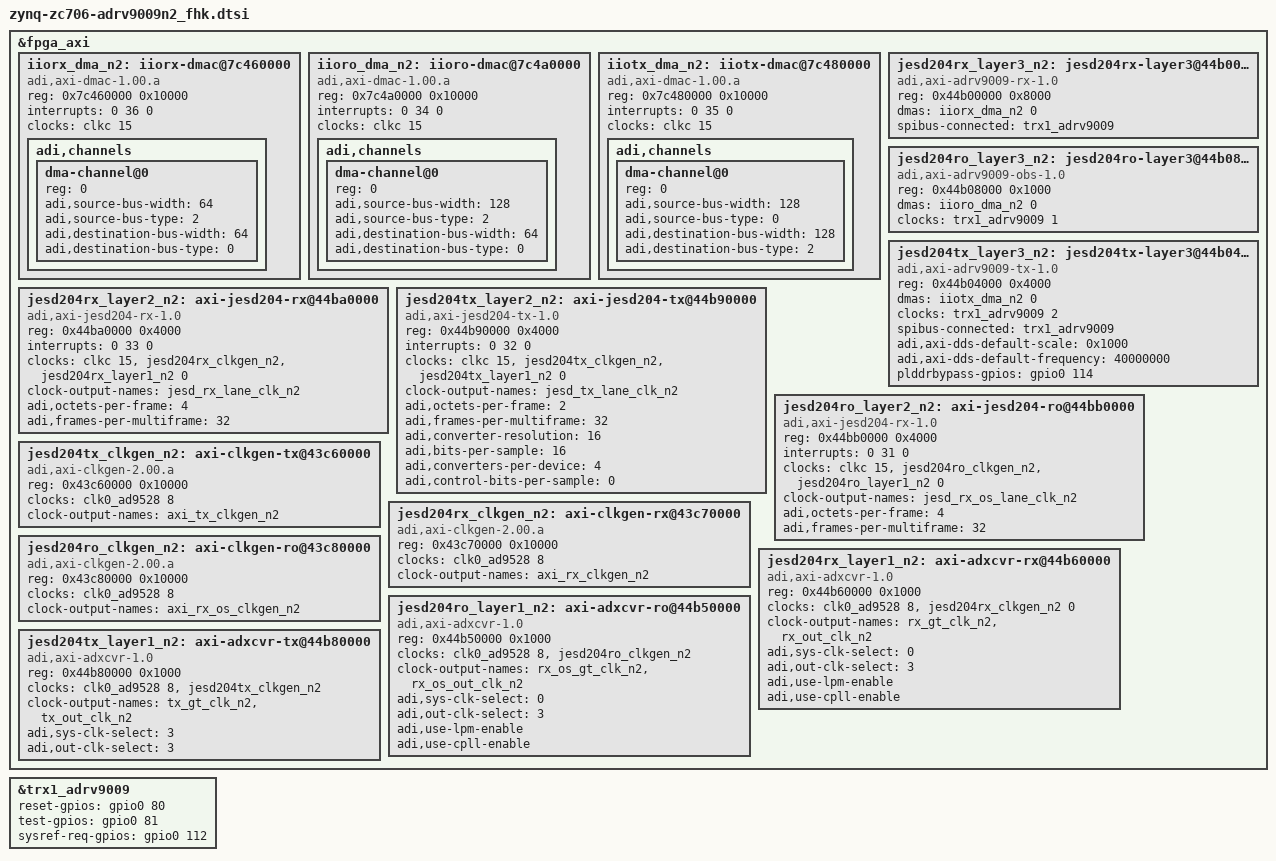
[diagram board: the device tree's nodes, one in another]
/* 
Author	: Jacky.Wang <kenwj@sina.com>
NOTICE	:
   clocks : means "clocks_input" actually
   clock-names : the name is "aligned" with the corresponding driver
interrupts of zynq7k:
  PL to PS Interrupts:
    IRQF2P[ 7: 0] input, SPI: Numbers [68:61].
    IRQF2P[15: 8] input, SPI: Numbers [91:84].
    IRQF2P[19:16] input, PPI: nFIQ, nIRQ (both CPUs).
  PS to PL Interrupts:
    IRQP2F[27: 0] Output, I/O peripherals received and forwarded to the interrupt controller.

History	:
  base: branch "adrv9009_zc706", "arch\arm\boot\dts\zynq-zc706-adv7511-adrv9009.dts"
  change: clock-tree/interrupts per FHK-RFB (1*AD9528+2*AD9009)
  reference: https://ez.analog.com/wide-band-rf-transceivers/
    design-support-adrv9008-1-adrv9008-2-adrv9009/f/discussions/
    100583/adrv9009-custom-profile/300558
  change: Xilinx DPD integration, FHK DMA datapath verification
*/
&fpga_axi {
	/* 0 (AXI_DMAC_TYPE_AXI_MM): Memory mapped AXI interface
	   1 (AXI_DMAC_TYPE_AXI_STREAM): Streaming AXI interface
	   2 (AXI_DMAC_TYPE_AXI_FIFO): FIFO interface */
	iiorx_dma_n2: iiorx-dmac@7c460000 {
		compatible = "adi,axi-dmac-1.00.a";
		reg = <0x7c460000 0x10000>;
		#dma-cells = <1>;
		interrupts = <0 36 0>; // UG858, Table 7-4: IRQF2P[7] -> IRQ[68-32]
		clocks = <&clkc 15>; // 15/fclk0=100MHz <- 17/fclk2=250MHz
		//clocks = <&clkc 15>, <&clkc 17>, <&misc_clk_0>;
		//clock-names = "s_axi_aclk", "m_dest_axi_aclk", "fifo_wr_clk";

		adi,channels {
			#size-cells = <0>;
			#address-cells = <1>;

			dma-channel@0 {
				reg = <0>;
				adi,source-bus-width = <64>;
				adi,source-bus-type = <2>;
				adi,destination-bus-width = <64>;
				adi,destination-bus-type = <0>;
			};
		};
	};

	iioro_dma_n2: iioro-dmac@7c4a0000  {
		compatible = "adi,axi-dmac-1.00.a";
		reg = <0x7c4a0000  0x10000>;
		#dma-cells = <1>;
		interrupts = <0 34 0>; // UG858, Table 7-4: IRQF2P[5] -> IRQ[66-32]
		clocks = <&clkc 15>; // 15/fclk0=100MHz <- 17/fclk2=250MHz
		//clocks = <&clkc 15>, <&clkc 17>, <&misc_clk_0>;
		//clock-names = "s_axi_aclk", "m_dest_axi_aclk", "fifo_wr_clk";

		adi,channels {
			#size-cells = <0>;
			#address-cells = <1>;

			dma-channel@0 {
				reg = <0>;
				adi,source-bus-width = <128>;// TODO: master for 122profile: 128
				adi,source-bus-type = <2>;
				adi,destination-bus-width = <64>;
				adi,destination-bus-type = <0>;
			};
		};
	};

	iiotx_dma_n2: iiotx-dmac@7c480000 {
		compatible = "adi,axi-dmac-1.00.a";
		reg = <0x7c480000 0x10000>;
		#dma-cells = <1>;
		interrupts = <0 35 0>; // UG858, Table 7-4: IRQF2P[6] -> IRQ[67-32]
		clocks = <&clkc 15>; // 15/fclk0=100MHz <- 17/fclk2=250MHz
		//clocks = <&clkc 15>, <&clkc 17>, <&clkc 17>;
		//clock-names = "s_axi_aclk", "m_src_axi_aclk", "m_axis_aclk";

		adi,channels {
			#size-cells = <0>;
			#address-cells = <1>;

			dma-channel@0 {
				reg = <0>;
				adi,source-bus-width = <128>;
				adi,source-bus-type = <0>;
				adi,destination-bus-width = <128>;
				adi,destination-bus-type = <2>;
				//adi,cyclic;
			};
		};
	};

	jesd204rx_layer3_n2: jesd204rx-layer3@44b00000 {
		compatible = "adi,axi-adrv9009-rx-1.0";
		reg = <0x44b00000 0x8000>;
		dmas = <&iiorx_dma_n2 0>;
		dma-names = "rx";
		spibus-connected = <&trx1_adrv9009>;
	};

	jesd204ro_layer3_n2: jesd204ro-layer3@44b08000 {
		compatible = "adi,axi-adrv9009-obs-1.0";
		reg = <0x44b08000 0x1000>;
		dmas = <&iioro_dma_n2 0>;
		dma-names = "rx";
		clocks = <&trx1_adrv9009 1>;
		clock-names = "sampl_clk";
	};

	jesd204tx_layer3_n2: jesd204tx-layer3@44b04000 {
		compatible = "adi,axi-adrv9009-tx-1.0";
		reg = <0x44b04000 0x4000>;
		dmas = <&iiotx_dma_n2 0>;
		dma-names = "tx";
		clocks = <&trx1_adrv9009 2>;
		clock-names = "sampl_clk";
		spibus-connected = <&trx1_adrv9009>;
		//adi,axi-pl-fifo-enable;/* "iio-stream" fail/succeed when true/false */

		//adi,axi-dds-parity-enable; bool
		//adi,axi-dds-parity-type-odd; bool
		//adi,axi-dds-1-rf-channel; bool
		adi,axi-dds-default-scale = <0x1000>;/* 0.250 */
		adi,axi-dds-default-frequency = <40000000>;
		//adi,axi-interpolation-core-available; bool
		//slavecore-reg; <u32_array>
	};

	jesd204rx_layer2_n2: axi-jesd204-rx@44ba0000 {
		compatible = "adi,axi-jesd204-rx-1.0";
		reg = <0x44ba0000 0x4000>;

		interrupts = <0 33 0>; // UG858, Table 7-4: IRQF2P[4] -> IRQ[65-32]

		clocks = <&clkc 15>, <&jesd204rx_clkgen_n2>, <&jesd204rx_layer1_n2 0>;
		clock-names = "s_axi_aclk", "device_clk", "lane_clk";

		#clock-cells = <0>;
		clock-output-names = "jesd_rx_lane_clk_n2";

		//RX_PATH: *FPGA.JESD204B-DeframerA -> PHY.JESD204B-FramerA
		//Figure 34. JESD204B Framer Configuration (M = 4, L = 2, S = 1)
		//adi,bits-per-sample = <16>;//N'=16; PHY-Framer decide
		//adi,converters-per-device = <4>;//M=4; PHY-Framer decide
		//L(Number of Lanes)=2; PHY-Framer decide
		//S(Number of Samples)=1; PHY-Framer decide(1,2,4)
		adi,octets-per-frame = <4>;//F=N'/8*M*S/L =(16/8)*4*1/2=4
		adi,frames-per-multiframe = <32>;
	};

	jesd204tx_layer2_n2: axi-jesd204-tx@44b90000 {
		compatible = "adi,axi-jesd204-tx-1.0";
		reg = <0x44b90000 0x4000>;

		interrupts = <0 32 0>; // UG858, Table 7-4: IRQF2P[3] -> IRQ[64-32]

		clocks = <&clkc 15>, <&jesd204tx_clkgen_n2>, <&jesd204tx_layer1_n2 0>;
		clock-names = "s_axi_aclk", "device_clk", "lane_clk";

		#clock-cells = <0>;
		clock-output-names = "jesd_tx_lane_clk_n2";

		//TX_PATH: *FPGA.JESD204B-FramerA -> PHY.JESD204B-DeframerA
		//L(Number of Lanes)=4; PHY-Deframer decide
		//S(Number of Samples)=1; PHY-Deframer decide(1-only)
		//Figure 36. JESD204B Framer Configuration (M = 4, L = 4, S = 1)
		adi,octets-per-frame = <2>;//F=N'/8*M*S/L =(16/8)*4*1/4=2
		adi,frames-per-multiframe = <32>;
		adi,converter-resolution = <16>;// 20190314: different from 14/zynqmp-zcu102-rev10-adrv9009.dts
		adi,bits-per-sample = <16>;//N'=16; PHY-Deframer decide
		adi,converters-per-device = <4>;//M=4; PHY-Deframer decide
		adi,control-bits-per-sample = <0>;// 20190314: different from 2/zynqmp-zcu102-rev10-adrv9009.dts
	};

	jesd204ro_layer2_n2: axi-jesd204-ro@44bb0000 {
		compatible = "adi,axi-jesd204-rx-1.0";
		reg = <0x44bb0000 0x4000>;

		interrupts = <0 31 0>; // UG858, Table 7-4: IRQF2P[2] -> IRQ[63-32]

		clocks = <&clkc 15>, <&jesd204ro_clkgen_n2>, <&jesd204ro_layer1_n2 0>;
		clock-names = "s_axi_aclk", "device_clk", "lane_clk";

		#clock-cells = <0>;
		clock-output-names = "jesd_rx_os_lane_clk_n2";

		//RO_PATH: *FPGA.JESD204B-DeframerB -> PHY.JESD204B-FramerB
		//option1: HW keep ORx1&2 setting(Figure 27. JESD204B Framer Configuration (M = 4, L = 2, S = 1)) but SW enable ORx2-only
		//option2: HW change into (Figure 13. Framer Data Packing for (M = 2, L = 1, S = 1))
		//stitching mode must setting with (M = 2, L = 2, logically), (M = 4, L = 2 physically)
		//adi,bits-per-sample = <16>;//N'=16; PHY-Framer decide
		//adi,converters-per-device = <2>;//PHY-Framer decide; must be 2 logically if ORX_rfbandwidth>200MHz
		//L(Number of Lanes)=2; PHY-Framer decide
		//S(Number of Samples)=1; PHY-Framer decide(1,2,or4)
		//F=N'/8*M*S/L: case1/orx-stitching=(16/8)*2*1/2=2; case2/orx-2chn=(16/8)*4*1/2=4;
		adi,octets-per-frame = <4>;
		adi,frames-per-multiframe = <32>;
	};

	jesd204tx_clkgen_n2: axi-clkgen-tx@43c60000  {
		compatible = "adi,axi-clkgen-2.00.a";
		reg = <0x43c60000 0x10000>;
		#clock-cells = <0>;
		clocks = <&clk0_ad9528 8>;
		clock-output-names = "axi_tx_clkgen_n2";
	};

	jesd204rx_clkgen_n2: axi-clkgen-rx@43c70000  {
		compatible = "adi,axi-clkgen-2.00.a";
		reg = <0x43c70000 0x10000>;
		#clock-cells = <0>;
		clocks = <&clk0_ad9528 8>;
		clock-output-names = "axi_rx_clkgen_n2";
	};

	jesd204ro_clkgen_n2: axi-clkgen-ro@43c80000  {
		compatible = "adi,axi-clkgen-2.00.a";
		reg = <0x43c80000 0x10000>;
		#clock-cells = <0>;
		clocks = <&clk0_ad9528 8>;
		clock-output-names = "axi_rx_os_clkgen_n2";
	};

	jesd204rx_layer1_n2: axi-adxcvr-rx@44b60000 {
		#address-cells = <1>;
		#size-cells = <0>;
		compatible = "adi,axi-adxcvr-1.0";
		reg = <0x44b60000 0x1000>;

		clocks = <&clk0_ad9528 8>, <&jesd204rx_clkgen_n2 0>;
		clock-names = "conv", "div40";

		#clock-cells = <1>;
		clock-output-names = "rx_gt_clk_n2", "rx_out_clk_n2";

		adi,sys-clk-select = <3>;//0->3: 20190320: using the shared QPLL(by Tx/Rx/ORx)
		adi,out-clk-select = <3>;
		adi,use-lpm-enable;
		//adi,use-cpll-enable;//20190320: using the shared QPLL(by Tx/Rx/ORx)
	};

	jesd204ro_layer1_n2: axi-adxcvr-ro@44b50000 {
		#address-cells = <1>;
		#size-cells = <0>;
		compatible = "adi,axi-adxcvr-1.0";
		reg = <0x44b50000 0x1000>;

		clocks = <&clk0_ad9528 8>, <&jesd204ro_clkgen_n2>;
		clock-names = "conv", "div40";

		#clock-cells = <1>;
		clock-output-names = "rx_os_gt_clk_n2", "rx_os_out_clk_n2";

		adi,sys-clk-select = <3>;//0->3: 20190320: using the shared QPLL(by Tx/Rx/ORx)
		adi,out-clk-select = <3>;
		adi,use-lpm-enable;
		//adi,use-cpll-enable;//20190320: using the shared QPLL(by Tx/Rx/ORx)
	};

	jesd204tx_layer1_n2: axi-adxcvr-tx@44b80000 {
		#address-cells = <1>;
		#size-cells = <0>;
		compatible = "adi,axi-adxcvr-1.0";
		reg = <0x44b80000 0x1000>;

		clocks = <&clk0_ad9528 8>, <&jesd204tx_clkgen_n2>;
		clock-names = "conv", "div40";

		#clock-cells = <1>;
		clock-output-names = "tx_gt_clk_n2", "tx_out_clk_n2";

		adi,sys-clk-select = <3>;// using QPLL for Tx, QPLL+CPLL for Rx/ORx
		adi,out-clk-select = <3>;
	};
};







#if 1 /* 122.88M-SPS: using QPLL for Tx, QPLL+CPLL for Rx/ORx */
#include "adi-adrv9009n2_fhk122dc122.dtsi"
	&jesd204rx_layer1_n2 {
		adi,sys-clk-select = <0>;
		adi,use-cpll-enable;
	};
	&jesd204ro_layer1_n2 {
		adi,sys-clk-select = <0>;
		adi,use-cpll-enable;
	};
#endif
#if 0 /* 245.76M-SPS: using QPLL-only for Tx/Rx/ORx */
#include "adi-adrv9009n2_fhk245dc245.dtsi"
#endif
#if 0 /* 491.52M-SPS: using QPLL-only for Tx/Rx/ORx */
#include "adi-adrv9009n2_fhk491dc245.dtsi"
//#include "adi-adrv9009n2_fhk491dc122.dtsi"
	&jesd204ro_layer2_n2 {
		adi,octets-per-frame = <2>;
	};
#endif




// adrv9009_tx1_enable,    // 31
// adrv9009_tx2_enable,    // 30
// adrv9009_rx1_enable,    // 29
// adrv9009_rx2_enable,    // 28
// adrv9009_test,          // 27
// adrv9009_reset_b,       // 26
// adrv9009_gpint,         // 25
// adrv9009_gpio_00,       // 24
// adrv9009_gpio_01,       // 23
// adrv9009_gpio_02,       // 22
// adrv9009_gpio_03,       // 21
// adrv9009_gpio_04,       // 20
// adrv9009_gpio_05,       // 19
// adrv9009_gpio_06,       // 18
// adrv9009_gpio_07,       // 17
// adrv9009_gpio_15,       // 16
// adrv9009_gpio_08,       // 15
// adrv9009_gpio_09,       // 14
// adrv9009_gpio_10,       // 13
// adrv9009_gpio_11,       // 12
// adrv9009_gpio_12,       // 11
// adrv9009_gpio_14,       // 10
// adrv9009_gpio_13,       //  9
// adrv9009_gpio_17,       //  8
// adrv9009_gpio_16,       //  7
// adrv9009_gpio_18}));    //  6 + 54

&trx1_adrv9009 {
	reset-gpios = <&gpio0 80 0>;
	test-gpios = <&gpio0 81 0>;
	sysref-req-gpios = <&gpio0 112 0>;
	/* FHK design: PL.RFESS.TDDC -> IO-signals -> RFIC & RFFC
	rx2-enable-gpios = <&gpio0 82 0>;
	rx1-enable-gpios = <&gpio0 83 0>;
	tx2-enable-gpios = <&gpio0 84 0>;
	tx1-enable-gpios = <&gpio0 85 0>;*/
};





&jesd204tx_layer3_n2 {
	plddrbypass-gpios = <&gpio0 114 0>;
};
